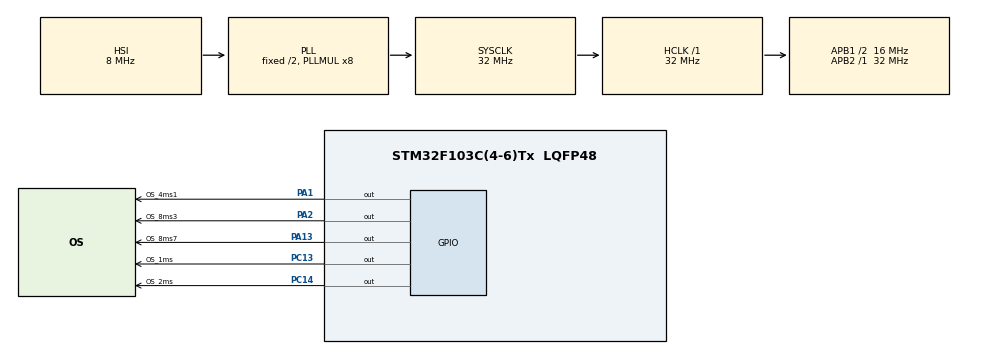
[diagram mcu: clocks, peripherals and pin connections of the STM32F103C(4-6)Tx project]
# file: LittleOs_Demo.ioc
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Mcu.Family=STM32F1
Mcu.Name=STM32F103C(4-6)Tx
Mcu.Package=LQFP48
NVIC.PriorityGroup=NVIC_PRIORITYGROUP_4
NVIC.TIM2_IRQn=true\:0\:0\:false\:false\:true\:true\:true\:true
PA1.GPIO_Label=OS_4ms1
PA1.Signal=GPIO_Output
PA13.GPIO_Label=OS_8ms7
PA13.Signal=GPIO_Output
PA2.GPIO_Label=OS_8ms3
PA2.Signal=GPIO_Output
PC13-TAMPER-RTC.GPIO_Label=OS_1ms
PC13-TAMPER-RTC.GPIO_PuPd=GPIO_PULLUP
PC13-TAMPER-RTC.PinState=GPIO_PIN_SET
PC13-TAMPER-RTC.Signal=GPIO_Output
PC14-OSC32_IN.GPIO_Label=OS_2ms
PC14-OSC32_IN.PinState=GPIO_PIN_SET
PC14-OSC32_IN.Signal=GPIO_Output
ProjectManager.HeapSize=0x200
ProjectManager.StackSize=0x400
ProjectManager.TargetToolchain=MDK-ARM V5.32
RCC.AHBFreq_Value=32000000
RCC.APB1CLKDivider=RCC_HCLK_DIV2
RCC.APB1Freq_Value=16000000
RCC.APB1TimFreq_Value=32000000
RCC.APB2Freq_Value=32000000
RCC.APB2TimFreq_Value=32000000
RCC.HCLKFreq_Value=32000000
RCC.PLLMUL=RCC_PLL_MUL8
RCC.SYSCLKFreq_VALUE=32000000
RCC.SYSCLKSource=RCC_SYSCLKSOURCE_PLLCLK
RCC.USBFreq_Value=32000000
TIM2.AutoReloadPreload=TIM_AUTORELOAD_PRELOAD_ENABLE
TIM2.Period=499
TIM2.Prescaler=63
VP_SYS_VS_ND.Mode=No_Debug
VP_TIM2_VS_ClockSourceINT.Mode=Internal
board=custom

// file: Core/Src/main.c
/* USER CODE BEGIN Header */
/**
  ******************************************************************************
  * @file           : main.c
  * @brief          : Main program body
  ******************************************************************************
  * @attention
  *
  * Copyright (c) 2023 STMicroelectronics.
  * All rights reserved.
  *
  * This software is licensed under terms that can be found in the LICENSE file
  * in the root directory of this software component.
  * If no LICENSE file comes with this software, it is provided AS-IS.
  *
  ******************************************************************************
  */
/* USER CODE END Header */
#include "main.h"
#include "tim.h"
#include "gpio.h"

/* USER CODE BEGIN Includes */
#include "OS.h"
/* USER CODE END Includes */

void SystemClock_Config(void);

int main(void)
{

  /* MCU Configuration--------------------------------------------------------*/

  /* Reset of all peripherals, Initializes the Flash interface and the Systick. */
  HAL_Init();

  /* Configure the system clock */
  SystemClock_Config();

  /* Initialize all configured peripherals */
  MX_GPIO_Init();
  MX_TIM2_Init();
  /* USER CODE BEGIN 2 */
  HAL_TIM_Base_Start_IT(&htim2);
  /* USER CODE END 2 */

  /* Infinite loop */
  while (1)
  {

    /* USER CODE BEGIN 3 */
	  OS();
	  //HAL_Delay(500);
	  //HAL_GPIO_TogglePin(Led3_GPIO_Port, Led3_Pin);
//	  if(Cnt == 1000)
//	  {
//		  HAL_GPIO_TogglePin(Led_GPIO_Port, Led_Pin);
//	  }
  }
  /* USER CODE END 3 */
}

void SystemClock_Config(void)
{
  RCC_OscInitTypeDef RCC_OscInitStruct = {0};
  RCC_ClkInitTypeDef RCC_ClkInitStruct = {0};

  /** Initializes the RCC Oscillators according to the specified parameters
  * in the RCC_OscInitTypeDef structure.
  */
  RCC_OscInitStruct.OscillatorType = RCC_OSCILLATORTYPE_HSI;
  RCC_OscInitStruct.HSIState = RCC_HSI_ON;
  RCC_OscInitStruct.HSICalibrationValue = RCC_HSICALIBRATION_DEFAULT;
  RCC_OscInitStruct.PLL.PLLState = RCC_PLL_ON;
  RCC_OscInitStruct.PLL.PLLSource = RCC_PLLSOURCE_HSI_DIV2;
  RCC_OscInitStruct.PLL.PLLMUL = RCC_PLL_MUL8;
  if (HAL_RCC_OscConfig(&RCC_OscInitStruct) != HAL_OK)
  {
    Error_Handler();
  }

  /** Initializes the CPU, AHB and APB buses clocks
  */
  RCC_ClkInitStruct.ClockType = RCC_CLOCKTYPE_HCLK|RCC_CLOCKTYPE_SYSCLK
                              |RCC_CLOCKTYPE_PCLK1|RCC_CLOCKTYPE_PCLK2;
  RCC_ClkInitStruct.SYSCLKSource = RCC_SYSCLKSOURCE_PLLCLK;
  RCC_ClkInitStruct.AHBCLKDivider = RCC_SYSCLK_DIV1;
  RCC_ClkInitStruct.APB1CLKDivider = RCC_HCLK_DIV2;
  RCC_ClkInitStruct.APB2CLKDivider = RCC_HCLK_DIV1;

  if (HAL_RCC_ClockConfig(&RCC_ClkInitStruct, FLASH_LATENCY_1) != HAL_OK)
  {
    Error_Handler();
  }
}

/* USER CODE BEGIN 4 */
void HAL_TIM_PeriodElapsedCallback(TIM_HandleTypeDef *htim)
{
	if (htim->Instance == TIM2)
	{

		LittleHeartFunc();
	}
}
/* USER CODE END 4 */

void Error_Handler(void)
{
  __disable_irq();
  while (1)
  {
  }
}
